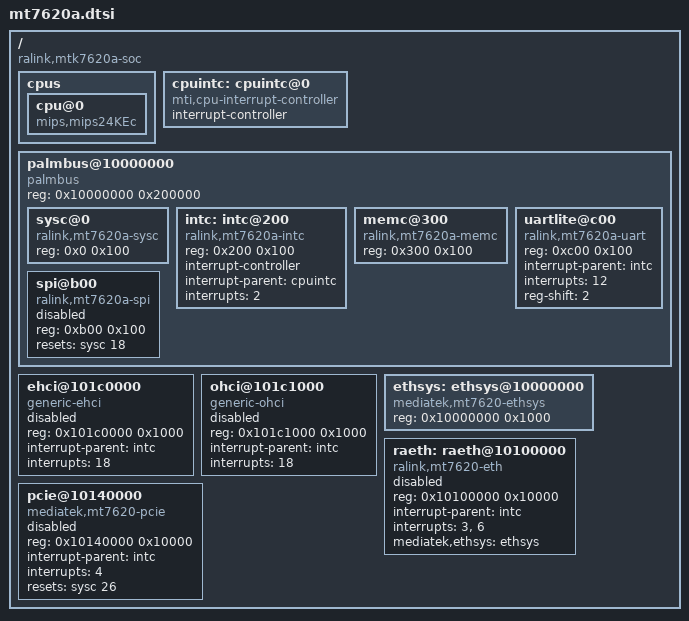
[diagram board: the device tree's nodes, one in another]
/ {
	#address-cells = <1>;
	#size-cells = <1>;
	compatible = "ralink,mtk7620a-soc";

	cpus {
		cpu@0 {
			compatible = "mips,mips24KEc";
		};
	};

	cpuintc: cpuintc@0 {
		#address-cells = <0>;
		#interrupt-cells = <1>;
		interrupt-controller;
		compatible = "mti,cpu-interrupt-controller";
	};

	palmbus@10000000 {
		compatible = "palmbus";
		reg = <0x10000000 0x200000>;
                ranges = <0x0 0x10000000 0x1FFFFF>;

		#address-cells = <1>;
		#size-cells = <1>;

		sysc@0 {
			compatible = "ralink,mt7620a-sysc";
			reg = <0x0 0x100>;
		};

		intc: intc@200 {
			compatible = "ralink,mt7620a-intc", "ralink,rt2880-intc";
			reg = <0x200 0x100>;

			interrupt-controller;
			#interrupt-cells = <1>;

			interrupt-parent = <&cpuintc>;
			interrupts = <2>;
		};

		memc@300 {
			compatible = "ralink,mt7620a-memc", "ralink,rt3050-memc";
			reg = <0x300 0x100>;
		};

		uartlite@c00 {
			compatible = "ralink,mt7620a-uart", "ralink,rt2880-uart", "ns16550a";
			reg = <0xc00 0x100>;

			interrupt-parent = <&intc>;
			interrupts = <12>;

			reg-shift = <2>;
		};

		spi@b00 {
			compatible = "ralink,mt7620a-spi", "ralink,rt2880-spi";
			reg = <0xb00 0x100>;

			resets = <&sysc 18>;
			reset-names = "spi";

			#address-cells = <1>;
			#size-cells = <0>;

			status = "disabled";
		};
	};

	ehci@101c0000 {
		compatible = "generic-ehci";
		reg = <0x101c0000 0x1000>;

		interrupt-parent = <&intc>;
		interrupts = <18>;

		status = "disabled";
	};

	ohci@101c1000 {
		compatible = "generic-ohci";
		reg = <0x101c1000 0x1000>;

		interrupt-parent = <&intc>;
		interrupts = <18>;

		status = "disabled";
	};

	ethsys: ethsys@10000000 {
		compatible = "mediatek,mt7620-ethsys", "syscon";
		reg = <0x10000000 0x1000>;
	};

	raeth: raeth@10100000 {
		compatible = "ralink,mt7620-eth";
		reg = <0x10100000 0x10000>;

		interrupt-parent = <&intc>;
		interrupts = <3>, <6>;

		mediatek,ethsys = <&ethsys>;

		status = "disabled";
	};

	pcie@10140000 {
		compatible = "mediatek,mt7620-pcie";
		reg = <0x10140000 0x10000>;

		interrupt-parent = <&intc>;
		interrupts = <4>;

		resets = <&sysc 26>;
		reset-names = "pcie";

		status = "disabled";
	};
};
